# SAMA7D65D1GN2 register map
Vendor: Microchip Technology; Series: SAMA7D6; File version: 0
Registers are 32-bit, read-write, reset 0x0 unless marked. A register's access mark holds for its fields unless they carry their own. Offsets are from the block's base; [hi:lo] are bit positions; {n}, {i} and the like mark numbered series; 'fields as' and 'values as' point back to an identical list.

## SFR — Special Function Register
Base 0xE181C000
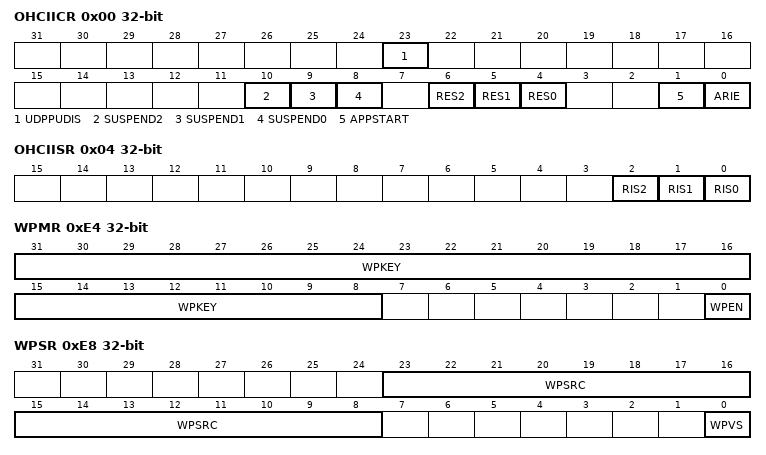
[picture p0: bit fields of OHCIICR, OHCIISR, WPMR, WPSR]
0x00 OHCIICR — OHCI Interrupt Configuration Register
  [23] UDPPUDIS
  [10] SUSPEND2 — USB PORT 2
    0=Suspends controlled by EHCI-OCHI; 1=Forces the suspend for PORTx
  [9] SUSPEND1 — USB PORT 1
    values as SUSPEND2
  [8] SUSPEND0 — USB PORT 0
    values as SUSPEND2
  [6] RES2 — USB PORTx Reset
    0=No effect (USB PORTx reset released, default value); 1=Resets USB PORTx
  [5] RES1 — USB PORTx Reset
    values as RES2
  [4] RES0 — USB PORTx Reset
    values as RES2
  [1] APPSTART
  [0] ARIE — OHCI Asynchronous Resume Interrupt Enable
    0=Interrupt is disabled; 1=Interrupt is enabled
0x04 OHCIISR ro — OHCI Interrupt Status Register
  [all] fields
    0=OHCI port resume not detected; 1=OHCI port resume detected
  [2] RIS2 — OHCI Resume Interrupt Status Port 2
  [1] RIS1 — OHCI Resume Interrupt Status Port 1
  [0] RIS0 — OHCI Resume Interrupt Status Port 0
0xE4 WPMR — Write Protection Mode Register
  [31:8] WPKEY — Write Protection Key
    0x534652=PASSWD (Writing any other value in this field aborts the write operation of the WPEN bit. Always reads as 0.)
  [0] WPEN — Write Protection Enable
    0=Disables the write protection if WPKEY value corresponds to 0x534652 ('SFR' in ASCII); 1=Enables the write protection if WPKEY value corresponds to 0x534652 ('SFR' in ASCII)
0xE8 WPSR ro — Write Protection Status Register
  [23:8] WPSRC — Write Protection Source
  [0] WPVS — Write Protection Violation Status
    0=No write protection violation has occurred since the last read of SFR_WPSR; 1=A write protection violation has occurred since the last read of SFR_WPSR. If this violation is an unauthorized attempt to write a protected register, the associated violation is reported into field WPSRC.
0x200C DEBUG
  [0] PROT — Protection Debug
    0=Protection debug is disabled; 1=Protection debug is enabled
0x202C MSK_ERR_DBG_MODE — Mask Error Debug Mode Register
  [0] DIS_DECERR — Disable Decode Error
    0=Enables decode error when reading a non-existing register in the UDDRC or GPU2DC user interface; 1=Disables decode error when reading a non-existing register in the UDDRC or GPU2DC user interface
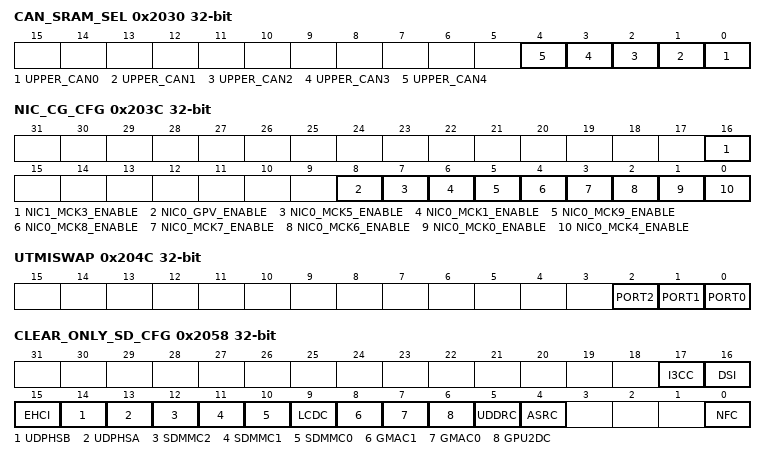
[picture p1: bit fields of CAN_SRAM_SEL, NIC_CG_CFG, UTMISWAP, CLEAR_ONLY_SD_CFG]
0x2030 CAN_SRAM_SEL — CAN SRAM Selection Register
  [all] fields
    0=CANx accesses the lower 64 Kb of SRAM; 1=CANx accesses the upper 64 Kb of SRAM
  [n] UPPER_CAN{n} (n=0..4) — CANx Upper 64K SRAM Selection
0x203C NIC_CG_CFG — NIC Clock Gating Configuration Register
  [16] NIC1_MCK3_ENABLE
    0=NIC1_MCK3_ENABLE clock gating disabled
  [8] NIC0_GPV_ENABLE
    0=NIC0_GPV_ENABLE clock gating disabled; 1=NIC0_GPV_ENABLE clock gating enabled
  [7] NIC0_MCK5_ENABLE
    0=NIC0_MCK5_ENABLE clock gating disabled
  [6] NIC0_MCK1_ENABLE
    0=NIC0_MCK1_ENABLE clock gating disabled; 1=NIC0_MCK1_ENABLE clock gating enabled
  [5] NIC0_MCK9_ENABLE
    0=NIC0_MCK9_ENABLE clock gating disabled; 1=NIC0_MCK9_ENABLE clock gating enabled
  [4] NIC0_MCK8_ENABLE
    0=NIC0_MCK8_ENABLE clock gating disabled; 1=NIC0_MCK8_ENABLE clock gating enabled
  [3] NIC0_MCK7_ENABLE
    0=NIC0_MCK7_ENABLE clock gating disabled
  [2] NIC0_MCK6_ENABLE
    0=NIC0_MCK6_ENABLE clock gating disabled; 1=NIC0_MCK6_ENABLE clock gating enabled
  [1] NIC0_MCK0_ENABLE
    0=NIC0_MCK0_ENABLE clock gating disabled; 1=NIC0_MCK0_ENABLE clock gating enabled
  [0] NIC0_MCK4_ENABLE
    0=NIC0_MCK4_ENABLE clock gating disabled; 1=NIC0_MCK4_ENABLE clock gating enabled
0x204C UTMISWAP — UTMI DP/DM Pin Swapping Register
  [all] fields
    0=NORMAL (DP/DM normal pinout); 1=SWAPPED (DP/DM swapped pinout)
  [2] PORT2 — Port 2 DP/DM Pin Swapping
  [1] PORT1 — Port 1 DP/DM Pin Swapping
  [0] PORT0 — Port 0 DP/DM Pin Swapping
0x2058 CLEAR_ONLY_SD_CFG — Memory Clear-Only Shutdown Configuration Register
  [17] I3CC — Shutdown Control Clear for Memories in I3C Controller
  [16] DSI — Shutdown Control Clear for Memories in MIPI DSI
  [15] EHCI — Shutdown Control Clear for Memories in USB EHCI
  [14] UDPHSB — Shutdown Control Clear for Memories in USB Device High-Speed Port B
  [13] UDPHSA — Shutdown Control Clear for Memories in USB Device High-Speed Port A
  [12] SDMMC2 — Shutdown Control Clear for Memories in SDMMC 2
  [11] SDMMC1 — Shutdown Control Clear for Memories in SDMMC 1
  [10] SDMMC0 — Shutdown Control Clear for Memories in SDMMC 0
  [9] LCDC — Shutdown Control Clear for Memories in LCD Controller
  [8] GMAC1 — Shutdown Control Clear for Memories in Ethernet MAC 1
  [7] GMAC0 — Shutdown Control Clear for Memories in Ethernet MAC 0
  [6] GPU2DC — Shutdown Control Clear for Memories in GPU2DC
  [5] UDDRC — Shutdown Control Clear for Memories in DDR Controller
  [4] ASRC — Shutdown Control Clear for Memories in Asynchronous Sample Rate Controller
  [0] NFC — Shutdown Control Clear for Memories in NFC
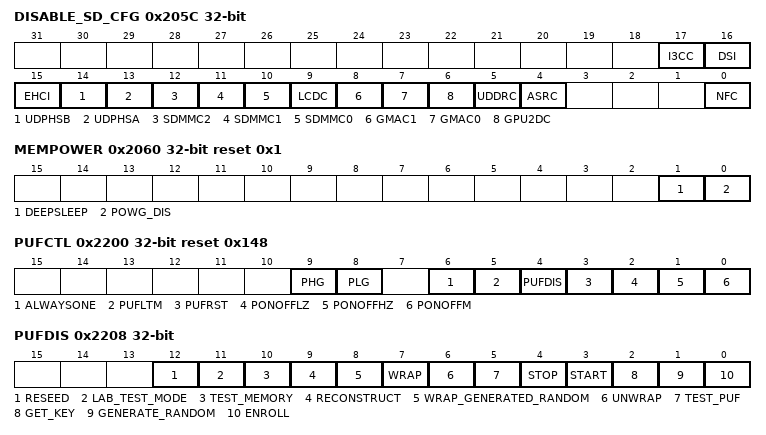
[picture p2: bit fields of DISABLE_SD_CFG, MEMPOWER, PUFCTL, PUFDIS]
0x205C DISABLE_SD_CFG — Memory Disable Shutdown Configuration Register
  [17] I3CC — Shutdown Control Disable for Memories in I3C Controller
  [16] DSI — Shutdown Control Disable for Memories in MIPI DSI
  [15] EHCI — Shutdown Control Disable for Memories in USB EHCI
  [14] UDPHSB — Shutdown Control Disable for Memories in USB Device High-Speed Port B
  [13] UDPHSA — Shutdown Control Disable for Memories in USB High-Speed Port A
  [12] SDMMC2 — Shutdown Control Disable for Memories in SDMMC 2
  [11] SDMMC1 — Shutdown Control Disable for Memories in SDMMC 1
  [10] SDMMC0 — Shutdown Control Disable for Memories in SDMMC 0
  [9] LCDC — Shutdown Control Disable for Memories in LCD Controller
  [8] GMAC1 — Shutdown Control Disable for Memories in Ethernet MAC 1
  [7] GMAC0 — Shutdown Control Disable for Memories in Ethernet MAC 0
  [6] GPU2DC — Shutdown Control Disable for Memories in GPU2DC
  [5] UDDRC — Shutdown Control Disable for Memories in DDR Controller
  [4] ASRC — Shutdown Control Disable for Memories in Asynchronous Sample Rate Controller
  [0] NFC — Shutdown Control Disable for Memories in NFC
0x2060 MEMPOWER reset 0x1 — Memory Power Mode Register
  [1] DEEPSLEEP — Automatic Memory Deep Sleep Mode for ULP1 Mode
    0=Memory Deep Sleep mode is disabled (Light Sleep mode is enabled); 1=Memory Deep Sleep mode is enabled
  [0] POWG_DIS — Automatic Memory Power Gating Disable for ULP1 Mode
    0=Automatic memory power gating is enabled; 1=Automatic memory power gating is disabled
0x2200 PUFCTL reset 0x148 — PUFSRAM Domain Control Register
  [9] PHG — PUFSRAM Power High Status (read-only)
    0=PUFSRAM domain is not powered; 1=PUFSRAM domain is powered
  [8] PLG — PUFSRAM Power Low Status (read-only)
    0=PUFSRAM domain is powered; 1=PUFSRAM domain is not powered
  [6] ALWAYSONE — Must always be programmed to 1
  [5] PUFLTM — PUF Lab Test Mode
    0=No effect; 1=Enters Test mode when PUFRST=0
  [4] PUFDIS — PUF Disable
    0=No effect; 1=PUF clock and access to the PUF are disabled by hardware and PUFSRAM domain is off
  [3] PUFRST — PUF Reset
    0=PUF is active; 1=PUF is in Reset mode
  [2] PONOFFLZ — Controls Power Switch LoZ if PONOFFM=1
    0=Power switch LoZ is off; 1=Power switch LoZ is on
  [1] PONOFFHZ — Controls Power Switch HiZ if PONOFFM=1
    0=Power switch HiZ is off; 1=Power switch HiZ is on
  [0] PONOFFM — PUFSRAM Power Switches Controlled Manually
    0=Power switches are automatically controlled by SYSC at start-up; 1=Power switches are manually controlled by the PONOFFLZ and PONOFFHZ bits
0x2208 PUFDIS — PUF Disable Functions Register
  [12] RESEED — Reseed Operation
  [11] LAB_TEST_MODE — Lab Test Mode Operation
  [10] TEST_MEMORY — Test Memory Operation
  [9] RECONSTRUCT — Reconstruct Operation
  [8] WRAP_GENERATED_RANDOM — Wrap Generated Random Operation
  [7] WRAP — Wrap Operation
  [6] UNWRAP — Unwrap Operation
  [5] TEST_PUF — Test PUF Operation
  [4] STOP — Stop Operation
  [3] START — Start Operation
  [2] GET_KEY — Get Key Operation
  [1] GENERATE_RANDOM — Generate Random Operation
  [0] ENROLL — Enroll Operation
{0x220C+4i} PUFRUCR[{i}] (i=0..1) — PUF Restrict User Context x Register
  [31:0] RESTRICT_USER_CONTEXT
    0=This bit can be used; 1=This bit cannot be used
{0x2214+4i} PUFWORUCR[{i}] (i=0..1) — PUF Restrict User Context x Write Ones Register
  [31:0] RESTRICT_USER_CONTEXT_WO — Restrict User Context
    0=This bit can be used; 1=This bit cannot be used
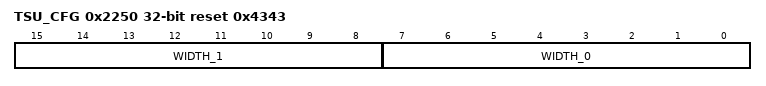
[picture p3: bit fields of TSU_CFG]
0x2250 TSU_CFG reset 0x4343 — TSU Configuration Register
  [15:8] WIDTH_1 — Number of TSU Cycles to Increase GTSUCOMP 1 Width
  [7:0] WIDTH_0 — Number of TSU Cycles to Increase GTSUCOMP 0 Width
